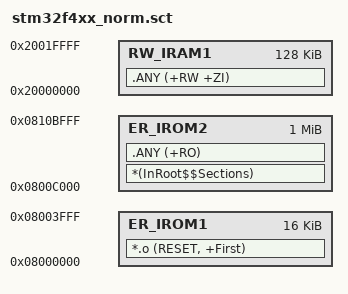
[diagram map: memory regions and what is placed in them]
; *************************************************************
; *** Scatter-Loading Description File generated by uVision ***
; *************************************************************

LR_IROM1 0x08000000 0x0004000  {    ; load region size_region
  ER_IROM1 0x08000000 0x0004000  {  ; load address = execution address
   *.o (RESET, +First)
  }
  RW_IRAM1 0x20000000 0x00020000  {  ; RW data
   .ANY (+RW +ZI)
  }
}

LR_IROM2 0x0800C000 0x00100000  {    ; load region size_region
  ER_IROM2 0x0800C000 0x00100000  {  ; load address = execution address
   *(InRoot$$Sections)
   .ANY (+RO)
  }
}
